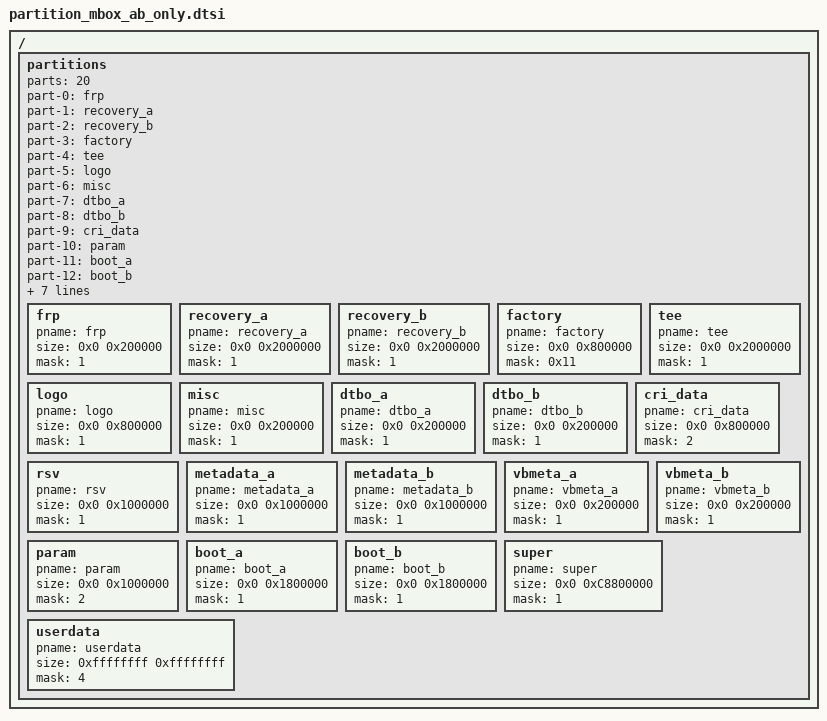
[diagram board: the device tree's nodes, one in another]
// SPDX-License-Identifier: (GPL-2.0+ OR MIT)
/*
 * Copyright (c) 2019 Amlogic, Inc. All rights reserved.
 */

#include "firmware_ab.dtsi"

/ {
    partitions: partitions{
		parts = <20>;
		part-0 = <&frp>;
		part-1 = <&recovery_a>;
		part-2 = <&recovery_b>;
		part-3 = <&factory>;
		part-4 = <&tee>;
		part-5 = <&logo>;
		part-6 = <&misc>;
		part-7 = <&dtbo_a>;
		part-8 = <&dtbo_b>;
		part-9 = <&cri_data>;
		part-10 = <&param>;
		part-11 = <&boot_a>;
		part-12 = <&boot_b>;
		part-13 = <&rsv>;
		part-14 = <&metadata_a>;
		part-15 = <&metadata_b>;
		part-16 = <&vbmeta_a>;
		part-17 = <&vbmeta_b>;
		part-18 = <&super>;
		part-19 = <&userdata>;

		frp:frp{
			pname = "frp";
			size = <0x0 0x200000>;
			mask = <1>;
		};
		recovery_a:recovery_a{
			pname = "recovery_a";
			size = <0x0 0x2000000>;
			mask = <1>;
		};
		recovery_b:recovery_b{
			pname = "recovery_b";
			size = <0x0 0x2000000>;
			mask = <1>;
		};
		factory:factory{
			pname = "factory";
			size = <0x0 0x800000>;
			mask = <0x11>;
		};
		tee:tee{
			pname = "tee";
			size = <0x0 0x2000000>;
			mask = <1>;
		};
		logo:logo{
			pname = "logo";
			size = <0x0 0x800000>;
			mask = <1>;
		};
		misc:misc{
			pname = "misc";
			size = <0x0 0x200000>;
			mask = <1>;
		};
		dtbo_a:dtbo_a{
			pname = "dtbo_a";
			size = <0x0 0x200000>;
			mask = <1>;
		};
		dtbo_b:dtbo_b{
			pname = "dtbo_b";
			size = <0x0 0x200000>;
			mask = <1>;
		};
		cri_data:cri_data
		{
			pname = "cri_data";
			size = <0x0 0x800000>;
			mask = <2>;
		};
		rsv:rsv{
			pname = "rsv";
			size = <0x0 0x1000000>;
			mask = <1>;
		};
		metadata_a:metadata_a{
			pname = "metadata_a";
			size = <0x0 0x1000000>;
			mask = <1>;
		};
		metadata_b:metadata_b{
			pname = "metadata_b";
			size = <0x0 0x1000000>;
			mask = <1>;
		};
		vbmeta_a:vbmeta_a{
			pname = "vbmeta_a";
			size = <0x0 0x200000>;
			mask = <1>;
		};
		vbmeta_b:vbmeta_b{
			pname = "vbmeta_b";
			size = <0x0 0x200000>;
			mask = <1>;
		};
		param:param{
			pname = "param";
			size = <0x0 0x1000000>;
			mask = <2>;
		};
		boot_a:boot_a
		{
			pname = "boot_a";
			size = <0x0 0x1800000>;
			mask = <1>;
		};
		boot_b:boot_b
		{
			pname = "boot_b";
			size = <0x0 0x1800000>;
			mask = <1>;
		};
		super:super
		{
			pname = "super";
			size = <0x0 0xC8800000>;
			mask = <1>;
		};
		userdata:userdata
		{
			pname = "userdata";
			size = <0xffffffff 0xffffffff>;
			mask = <4>;
		};
	};
};/* end of / */
